# SA3_SS0_PKTDMA_0_PKTDMA_CFG_RCHANRT register map
Vendor: Texas Instruments
Peripheral module from a debugger description file (folder am62P).
Registers are 32-bit, read-write, reset 0x0 unless marked. A register's access mark holds for its fields unless they carry their own. Offsets are as the file gives them; lines under a group give offsets from that group; [hi:lo] are bit positions; {n}, {i} and the like mark numbered series; 'fields as' and 'values as' point back to an identical list; <NAME> marks a mode.

## SA3_SS0_PKTDMA_0_PKTDMA_CFG_RCHANRT
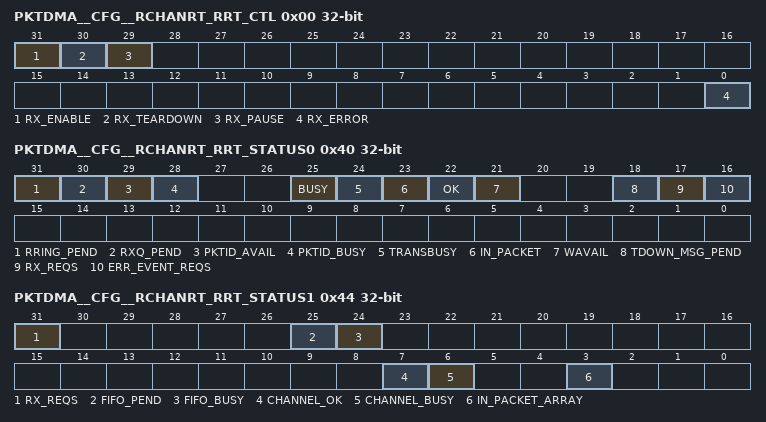
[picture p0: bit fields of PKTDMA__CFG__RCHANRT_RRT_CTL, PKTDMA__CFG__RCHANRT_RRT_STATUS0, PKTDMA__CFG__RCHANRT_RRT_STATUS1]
0x00 PKTDMA__CFG__RCHANRT_RRT_CTL — The Rx Channel Realtime Control Register contains real-time control and status information for the Rx DMA channel. The fields in this register can safely be changed while the channel is in operation.
  [31] RX_ENABLE — This field enables or disables the channel. Disabling a channel halts operation on the channel after the current block transfer is completed. Disabling a channel in the middle of a packet transfer may result in overflow conditions in the attached application and data loss. When a channel is disabled, the implementation may choose to reset all state for the channel. The pause bit should be asserted instead of clearing enable directly if the intent is to temporarily pause the channel. This field is encoded as follows: 0 = channel is disabled 1 = channel is enabled This field will be cleared by HW after a teardown is requested to indicate tha the channel teardown is complete. If the host is enabling a channel that is just being set up, the host must initialize all of the other channel configuration fields before setting this bit.
  [30] RX_TEARDOWN — This field indicates whether or not an Rx teardown operation is complete. This field should be cleared when a channel is initialized. This field will be set after a channel teardown is complete.
  [29] RX_PAUSE — Channel pause: Setting this bit will cause the channel to pause processing immediately.
  [0] RX_ERROR — Channel error: This bit will be set anytime an error has occurred on the channel. This bit is cleared when the channel is disabled and re-enabled.
0x40 PKTDMA__CFG__RCHANRT_RRT_STATUS0 ro — The Status Register provides a read only view of channel status bits.
  [31] RRING_PEND — The channel ring has a descriptor
  [30] RXQ_PEND — The channel fifo is available
  [29] PKTID_AVAIL — The channel has an available packet id
  [28] PKTID_BUSY — There is an outstanding pktid for the channel
  [25] BUSY — The channel is busy
  [24] TRANSBUSY — The channel has an outstanding transaction
  [23] IN_PACKET — The channel is currently in a packet
  [22] OK — The channel is ready to be scheduled
  [21] WAVAIL — The fifo for the channel has space to place a burst size entry
  [18] TDOWN_MSG_PEND — A teardown message is pending
  [17] RX_REQS — The channel is sending a schedule request
  [16] ERR_EVENT_REQS — The channel is trying to schedule an error event
0x44 PKTDMA__CFG__RCHANRT_RRT_STATUS1 ro — The Status Register provides a read only view of channel status bits.
  [31] RX_REQS — The channel is sending a schedule request
  [25] FIFO_PEND — The FIFO has enough data for a burst
  [24] FIFO_BUSY — The fifo has data
  [7] CHANNEL_OK — The channel is trying to schedule work
  [6] CHANNEL_BUSY — The channel has active work
  [3] IN_PACKET_ARRAY — The channel is in a packet
0x80 PKTDMA__CFG__RCHANRT_RRT_STDATA — The State Data Registers contain the current working state of the Rx DMA channel. These registers are provided so that the Host can determine the potential cause of an error or exception condition which was reported by the channel. These registers should not be accessed without reason while the PKTDMA is operating as accesses will cause performance to decrease as these MMRs are just providing a window into the actual state RAM
  [31:0] STATE_INFO
{0x200+4i} PKTDMA__CFG__RCHANRT_RRT_PEER{i} (i=0..15) — This register provides access to the remote peer's realtime register at {0x400+i}.
  [31:0] PEER_DATA — Peer realtime register data (varies by paired peer).
0x400 PKTDMA__CFG__RCHANRT_RRT_PCNT access not given — The statistics registers are supplied to give software applications operational progress status for the channel.
  [31:0] PCNT — Current completed packet count for the channel. (access R/WTD)
0x404 PKTDMA__CFG__RCHANRT_RRT_DCNT access not given — The statistics registers are supplied to give software applications operational progress status for the channel.
  [31:0] DCNT — Current dropped packet count for the channel. (access R/WTD)
0x408 PKTDMA__CFG__RCHANRT_RRT_BCNT access not given — The statistics registers are supplied to give software applications operational progress status for the channel.
  [31:0] BCNT — Current completed payload byte count for the channel. (access R/WTD)
0x410 PKTDMA__CFG__RCHANRT_RRT_SBCNT access not given — The statistics registers are supplied to give software applications operational progress status for the channel.
  [31:0] SBCNT — Current started byte count for the channel. (access R/WTD)
